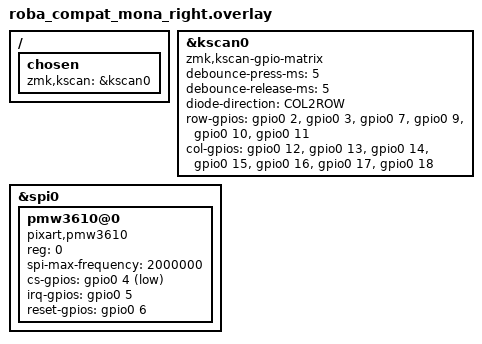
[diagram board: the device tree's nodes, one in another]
/* RIGHT (Peripheral) */
#include "../common/common.keymap"

/ { chosen { zmk,kscan = &kscan0; }; };

&kscan0 {
  compatible = "zmk,kscan-gpio-matrix";
  status = "okay";
  debounce-press-ms = <5>;
  debounce-release-ms = <5>;
  diode-direction = "COL2ROW";
  row-gpios = <&gpio0 2 GPIO_ACTIVE_HIGH>,
              <&gpio0 3 GPIO_ACTIVE_HIGH>,
              <&gpio0 7 GPIO_ACTIVE_HIGH>,
              <&gpio0 9 GPIO_ACTIVE_HIGH>,
              <&gpio0 10 GPIO_ACTIVE_HIGH>,
              <&gpio0 11 GPIO_ACTIVE_HIGH>;
  col-gpios = <&gpio0 12 GPIO_ACTIVE_HIGH>,
              <&gpio0 13 GPIO_ACTIVE_HIGH>,
              <&gpio0 14 GPIO_ACTIVE_HIGH>,
              <&gpio0 15 GPIO_ACTIVE_HIGH>,
              <&gpio0 16 GPIO_ACTIVE_HIGH>,
              <&gpio0 17 GPIO_ACTIVE_HIGH>,
              <&gpio0 18 GPIO_ACTIVE_HIGH>;
};

/* PMW3610 on SPI */
&spi0 {
  status = "okay";
  pmw3610@0 {
    compatible = "pixart,pmw3610";
    status = "okay";
    reg = <0>;
    spi-max-frequency = <2000000>;
    cs-gpios    = <&gpio0 4 GPIO_ACTIVE_LOW>;
    irq-gpios   = <&gpio0 5 GPIO_ACTIVE_HIGH>;
    reset-gpios = <&gpio0 6 GPIO_ACTIVE_HIGH>;
  };
};
